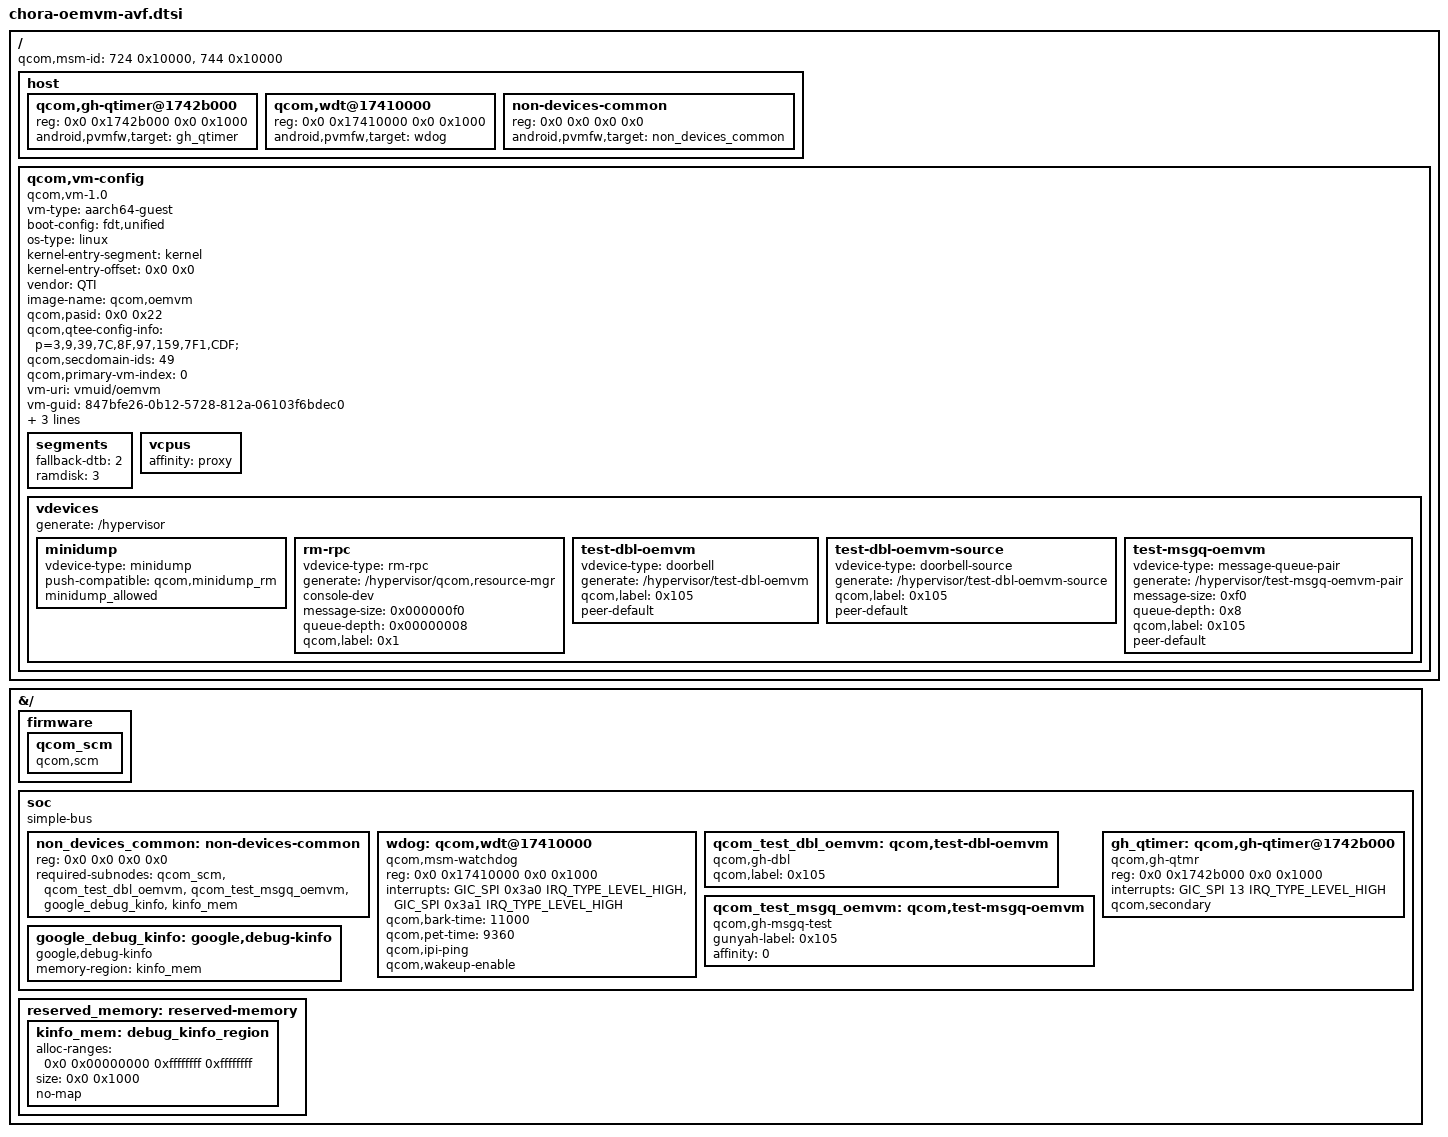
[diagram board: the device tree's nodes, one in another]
// SPDX-License-Identifier: BSD-3-Clause
/*
 * Copyright (c) Qualcomm Technologies, Inc. and/or its subsidiaries.
 */

#include <dt-bindings/interrupt-controller/arm-gic.h>

/ {
	#address-cells = <0x2>;
	#size-cells = <0x2>;
	qcom,msm-id = <724 0x10000>, <744 0x10000>;

	host {
		#address-cells = <0x2>;
		#size-cells = <0x2>;

		qcom,gh-qtimer@1742b000 {
			reg = <0x0 0x1742b000 0x0 0x1000>;
			android,pvmfw,target = <&gh_qtimer>;
		};

		qcom,wdt@17410000 {
			reg = <0x0 0x17410000 0x0 0x1000>;
			android,pvmfw,target = <&wdog>;
		};

		non-devices-common {
			reg = <0x0 0x0 0x0 0x0>;
			android,pvmfw,target = <&non_devices_common>;
		};
	};

	qcom,vm-config {
		compatible = "qcom,vm-1.0";
		vm-type = "aarch64-guest";
		boot-config = "fdt,unified";
		os-type = "linux";
		kernel-entry-segment = "kernel";
		kernel-entry-offset = <0x0 0x0>;
		vendor = "QTI";
		image-name = "qcom,oemvm";
		qcom,pasid = <0x0 0x22>;
		qcom,qtee-config-info = "p=3,9,39,7C,8F,97,159,7F1,CDF;";
		qcom,secdomain-ids = <49>;
		qcom,primary-vm-index = <0>;
		vm-uri = "vmuid/oemvm";
		vm-guid = "847bfe26-0b12-5728-812a-06103f6bdec0";

		vm-attrs = "context-dump", "crash-restart", "no-vpm-aggregation";

		/*
		 * Allow VMMIO traps. Currently doesn't include
		 * PVTIME, VIRTFREQ and GIC virtual devices.
		 * GIC is emulated by Gunyah.
		 */
		vmmio-ranges;

		segments {
			fallback-dtb = <2>;
			ramdisk = <3>;
		};

		vcpus {
			affinity = "proxy";
		};

		vdevices {
			generate = "/hypervisor";

			minidump {
				vdevice-type = "minidump";
				push-compatible = "qcom,minidump_rm";
				minidump_allowed;
			};

			rm-rpc {
				vdevice-type = "rm-rpc";
				generate = "/hypervisor/qcom,resource-mgr";
				console-dev;
				message-size = <0x000000f0>;
				queue-depth = <0x00000008>;
				qcom,label = <0x1>;
			};

			test-dbl-oemvm {
				vdevice-type = "doorbell";
				generate = "/hypervisor/test-dbl-oemvm";
				qcom,label = <0x105>;
				peer-default;
			};

			test-dbl-oemvm-source {
				vdevice-type = "doorbell-source";
				generate = "/hypervisor/test-dbl-oemvm-source";
				qcom,label = <0x105>;
				peer-default;
			};

			test-msgq-oemvm {
				vdevice-type = "message-queue-pair";
				generate = "/hypervisor/test-msgq-oemvm-pair";
				message-size = <0xf0>;
				queue-depth = <0x8>;
				qcom,label = <0x105>;
				peer-default;
			};
		};
	};
};

&{/} {
	#address-cells = <0x2>;
	#size-cells = <0x2>;

	firmware: firmware {
		qcom_scm: qcom_scm {
			compatible = "qcom,scm";
		};
	};

	soc: soc { };

	reserved_memory: reserved-memory {
		#address-cells = <2>;
		#size-cells = <2>;
		ranges;
	};
};

&reserved_memory {
	kinfo_mem: debug_kinfo_region {
		alloc-ranges = <0x0 0x00000000 0xffffffff 0xffffffff>;
		size = <0x0 0x1000>;
		no-map;
	};
};

&soc {
	#address-cells = <2>;
	#size-cells = <2>;
	ranges = <0x0 0x0 0x0 0x0 0x0 0xffffffff>;
	compatible = "simple-bus";

	non_devices_common: non-devices-common {
		reg = <0x0 0x0 0x0 0x0>;
		required-subnodes = <&qcom_scm
				&qcom_test_dbl_oemvm
				&qcom_test_msgq_oemvm
				&google_debug_kinfo
				&kinfo_mem
				>;
	};

	wdog: qcom,wdt@17410000 {
		compatible = "qcom,msm-watchdog";
		reg = <0x0 0x17410000 0x0 0x1000>;
		reg-names = "wdt-base";
		interrupts = <GIC_SPI 0x3a0 IRQ_TYPE_LEVEL_HIGH>,
			<GIC_SPI 0x3a1 IRQ_TYPE_LEVEL_HIGH>;
		qcom,bark-time = <11000>;
		qcom,pet-time = <9360>;
		qcom,ipi-ping;
		qcom,wakeup-enable;
	};

	qcom_test_dbl_oemvm: qcom,test-dbl-oemvm {
		compatible = "qcom,gh-dbl";
		qcom,label = <0x105>;
	};

	qcom_test_msgq_oemvm: qcom,test-msgq-oemvm {
		compatible = "qcom,gh-msgq-test";
		gunyah-label = <0x105>;
		affinity = <0>;
	};

	gh_qtimer: qcom,gh-qtimer@1742b000 {
		compatible = "qcom,gh-qtmr";
		reg = <0x0 0x1742b000 0x0 0x1000>;
		reg-names = "qtmr-base";
		interrupts = <GIC_SPI 13 IRQ_TYPE_LEVEL_HIGH>;
		interrupt-names = "qcom,qtmr-intr";
		qcom,secondary;
	};

	google_debug_kinfo: google,debug-kinfo {
		compatible = "google,debug-kinfo";
		memory-region = <&kinfo_mem>;
	};
};

#include "chora-oemvm-rm-info-avf.dtsi"
